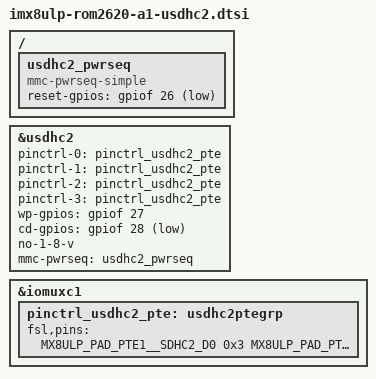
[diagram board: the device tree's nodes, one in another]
/ {
	usdhc2_pwrseq: usdhc2_pwrseq {
		compatible = "mmc-pwrseq-simple";
		reset-gpios = <&gpiof 26 GPIO_ACTIVE_LOW>;
	};
};

&usdhc2 {
	pinctrl-names = "default", "state_100mhz", "state_200mhz", "sleep";
	pinctrl-0 = <&pinctrl_usdhc2_pte>;
	pinctrl-1 = <&pinctrl_usdhc2_pte>;
	pinctrl-2 = <&pinctrl_usdhc2_pte>;
	pinctrl-3 = <&pinctrl_usdhc2_pte>;
	wp-gpios = <&gpiof 27 GPIO_ACTIVE_HIGH>;
	cd-gpios = <&gpiof 28 GPIO_ACTIVE_LOW>;
	no-1-8-v;
	mmc-pwrseq = <&usdhc2_pwrseq>;
	/delete-property/ non-removable;
	/delete-property/ wakeup-source;
	/delete-node/ wifi_wake_host;
};

&iomuxc1 {
	pinctrl_usdhc2_pte: usdhc2ptegrp {
		fsl,pins = <
			MX8ULP_PAD_PTE1__SDHC2_D0	0x3
			MX8ULP_PAD_PTE0__SDHC2_D1	0x3
			MX8ULP_PAD_PTE5__SDHC2_D2	0x3
			MX8ULP_PAD_PTE4__SDHC2_D3	0x3
			MX8ULP_PAD_PTE2__SDHC2_CLK	0x10002
			MX8ULP_PAD_PTE3__SDHC2_CMD	0x3
			MX8ULP_PAD_PTF26__SDHC2_RESET_B	0x3
			MX8ULP_PAD_PTF27__SDHC2_WP	0x2
			MX8ULP_PAD_PTF28__SDHC2_CD	0x3
		>;
	};
};
